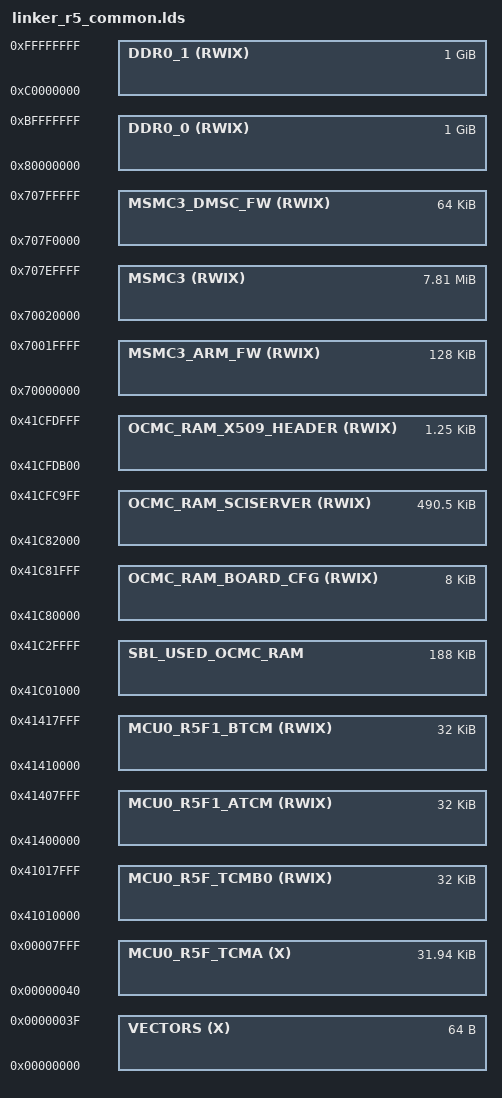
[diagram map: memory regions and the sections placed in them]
/*
 *
 * Copyright (c) 2025 Texas Instruments Incorporated
 *
 * All rights reserved not granted herein.
 *
 * Limited License.
 *
 * Texas Instruments Incorporated grants a world-wide, royalty-free, non-exclusive
 * license under copyrights and patents it now or hereafter owns or controls to make,
 * have made, use, import, offer to sell and sell ("Utilize") this software subject to the
 * terms herein.  With respect to the foregoing patent license, such license is granted
 * solely to the extent that any such patent is necessary to Utilize the software alone.
 * The patent license shall not apply to any combinations which include this software,
 * other than combinations with devices manufactured by or for TI ("TI Devices").
 * No hardware patent is licensed hereunder.
 *
 * Redistributions must preserve existing copyright notices and reproduce this license
 * (including the above copyright notice and the disclaimer and (if applicable) source
 * code license limitations below) in the documentation and/or other materials provided
 * with the distribution
 *
 * Redistribution and use in binary form, without modification, are permitted provided
 * that the following conditions are met:
 *
 * *       No reverse engineering, decompilation, or disassembly of this software is
 * permitted with respect to any software provided in binary form.
 *
 * *       any redistribution and use are licensed by TI for use only with TI Devices.
 *
 * *       Nothing shall obligate TI to provide you with source code for the software
 * licensed and provided to you in object code.
 *
 * If software source code is provided to you, modification and redistribution of the
 * source code are permitted provided that the following conditions are met:
 *
 * *       any redistribution and use of the source code, including any resulting derivative
 * works, are licensed by TI for use only with TI Devices.
 *
 * *       any redistribution and use of any object code compiled from the source code
 * and any resulting derivative works, are licensed by TI for use only with TI Devices.
 *
 * Neither the name of Texas Instruments Incorporated nor the names of its suppliers
 *
 * may be used to endorse or promote products derived from this software without
 * specific prior written permission.
 *
 * DISCLAIMER.
 *
 * THIS SOFTWARE IS PROVIDED BY TI AND TI'S LICENSORS "AS IS" AND ANY EXPRESS
 * OR IMPLIED WARRANTIES, INCLUDING, BUT NOT LIMITED TO, THE IMPLIED WARRANTIES
 * OF MERCHANTABILITY AND FITNESS FOR A PARTICULAR PURPOSE ARE DISCLAIMED.
 * IN NO EVENT SHALL TI AND TI'S LICENSORS BE LIABLE FOR ANY DIRECT, INDIRECT,
 * INCIDENTAL, SPECIAL, EXEMPLARY, OR CONSEQUENTIAL DAMAGES (INCLUDING,
 * BUT NOT LIMITED TO, PROCUREMENT OF SUBSTITUTE GOODS OR SERVICES; LOSS OF USE,
 * DATA, OR PROFITS; OR BUSINESS INTERRUPTION) HOWEVER CAUSED AND ON ANY THEORY
 * OF LIABILITY, WHETHER IN CONTRACT, STRICT LIABILITY, OR TORT (INCLUDING NEGLIGENCE
 * OR OTHERWISE) ARISING IN ANY WAY OUT OF THE USE OF THIS SOFTWARE, EVEN IF ADVISED
 * OF THE POSSIBILITY OF SUCH DAMAGE.
 *
 */
 
 /*=========================*/
/*     Linker Settings     */
/*=========================*/

--retain="*(.bootCode)"
--retain="*(.startupCode)"
--retain="*(.startupData)"
--retain="*(.irqStack)"
--retain="*(.fiqStack)"
--retain="*(.abortStack)"
--retain="*(.undStack)"
--retain="*(.svcStack)"

--fill_value=0
--stack_size=0x4000
--heap_size=0x1000
--entry_point=_freertosresetvectors

-stack  0x4000  /* SOFTWARE STACK SIZE */
-heap   0x1000  /* HEAP AREA SIZE      */

/*-------------------------------------------*/
/*       Stack Sizes for various modes       */
/*-------------------------------------------*/
__IRQ_STACK_SIZE   = 0x100;
__FIQ_STACK_SIZE   = 0x100;
__ABORT_STACK_SIZE = 0x100;
__UND_STACK_SIZE   = 0x100;
__SVC_STACK_SIZE   = 0x100;

/*--------------------------------------------------------------------------*/
/*                               Memory Map                                 */
/*--------------------------------------------------------------------------*/
MEMORY
{
    VECTORS (X)                 : ORIGIN = 0x00000000 LENGTH = 0x00000040

    /*=================== MCU0_R5F_0 Local View ========================*/
    MCU0_R5F_TCMA  (X)          : ORIGIN = 0x00000040 LENGTH = 0x00007FC0
    MCU0_R5F_TCMB0 (RWIX)       : ORIGIN = 0x41010000 LENGTH = 0x00008000

    /*==================== MCU0_R5F_1 SoC View =========================*/
    MCU0_R5F1_ATCM (RWIX)       : ORIGIN = 0x41400000 LENGTH = 0x00008000
    MCU0_R5F1_BTCM (RWIX)       : ORIGIN = 0x41410000 LENGTH = 0x00008000

    /*- Refer user guide for details on persistence of these sections -*/
    SBL_USED_OCMC_RAM           : ORIGIN = 0x41C01000 LENGTH = 0x0002F000
    OCMC_RAM_BOARD_CFG   (RWIX) : ORIGIN = 0x41C80000 LENGTH = 0x00002000
    OCMC_RAM_SCISERVER   (RWIX) : ORIGIN = 0x41C82000 LENGTH = 0x0007AA00
    OCMC_RAM_X509_HEADER (RWIX) : ORIGIN = 0x41CFDB00 LENGTH = 0x00000500

    /*========================J7200 MCMS3 LOCATIONS ===================*/
    /*---------- J7200 Reserved Memory for ARM Trusted Firmware -------*/
    MSMC3_ARM_FW  (RWIX)        : ORIGIN = 0x70000000 LENGTH = 0x00020000   /* 128KB       */
    MSMC3         (RWIX)        : ORIGIN = 0x70020000 LENGTH = 0x007D0000   /* 8MB - 192KB */
    /*------------- J7200 Reserved Memory for DMSC Firmware -----------*/
    MSMC3_DMSC_FW (RWIX)        : ORIGIN = 0x707F0000 LENGTH = 0x00010000   /* 64KB        */

    /*======================= J7200 DDR LOCATION =======================*/
    DDR0_0 (RWIX)                 : ORIGIN = 0x80000000 LENGTH = 0x40000000   /* 1GB */
    DDR0_1 (RWIX)                 : ORIGIN = 0xC0000000 LENGTH = 0x40000000   /* 1GB */
}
